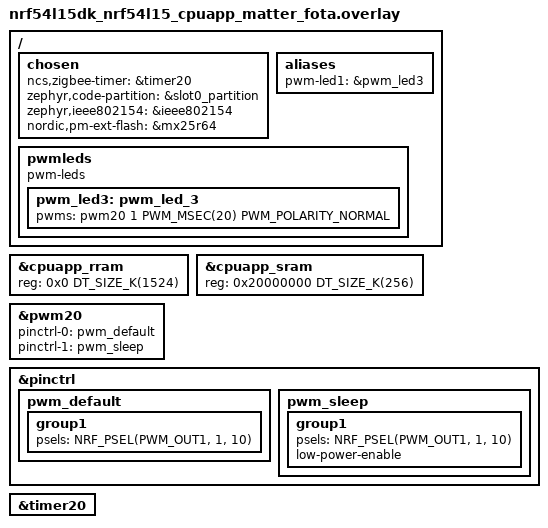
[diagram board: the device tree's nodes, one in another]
/*
 * Copyright (c) 2026 Nordic Semiconductor ASA
 *
 * SPDX-License-Identifier: LicenseRef-Nordic-5-Clause
 */

#include <matter/nrf54l15dk_cpuapp_partitions_ext_flash.dtsi>

/ {
	chosen {
		ncs,zigbee-timer = &timer20;
		zephyr,code-partition = &slot0_partition;
		zephyr,ieee802154 = &ieee802154;
		nordic,pm-ext-flash = &mx25r64;
	};

	aliases {
		pwm-led1 = &pwm_led3;
	};

	pwmleds {
		compatible = "pwm-leds";

		pwm_led3: pwm_led_3 {
			pwms = <&pwm20 1 PWM_MSEC(20) PWM_POLARITY_NORMAL>;
		};
	};
};

&cpuapp_rram {
	reg = <0x0 DT_SIZE_K(1524)>;
};

&cpuapp_sram {
	reg = <0x20000000 DT_SIZE_K(256)>;
	ranges = <0x0 0x20000000 0x40000>;
};

&pwm20 {
	status = "okay";
	pinctrl-0 = <&pwm_default>;
	pinctrl-1 = <&pwm_sleep>;
	pinctrl-names = "default", "sleep";
};

&pinctrl {
	pwm_default: pwm_default {
		group1 {
			psels = <NRF_PSEL(PWM_OUT1, 1, 10)>;
		};
	};

	pwm_sleep: pwm_sleep {
		group1 {
			psels = <NRF_PSEL(PWM_OUT1, 1, 10)>;
			low-power-enable;
		};
	};
};

&timer20 {
	status = "okay";
};
